# LPC865 register map
Vendor: nxp.com; File version: 1.0
CPU: CM0PLUS r0p0, little endian, no MPU, no FPU, VTOR, 2 interrupt priority bits
Registers are 32-bit, read-write, reset 0x0 unless marked. A register's access mark holds for its fields unless they carry their own. Offsets are from the block's base; [hi:lo] are bit positions; {n}, {i} and the like mark numbered series; 'fields as' and 'values as' point back to an identical list.

## ADC0 — LPC84x 12-bit ADC controller (ADC)
Base 0x4001C000
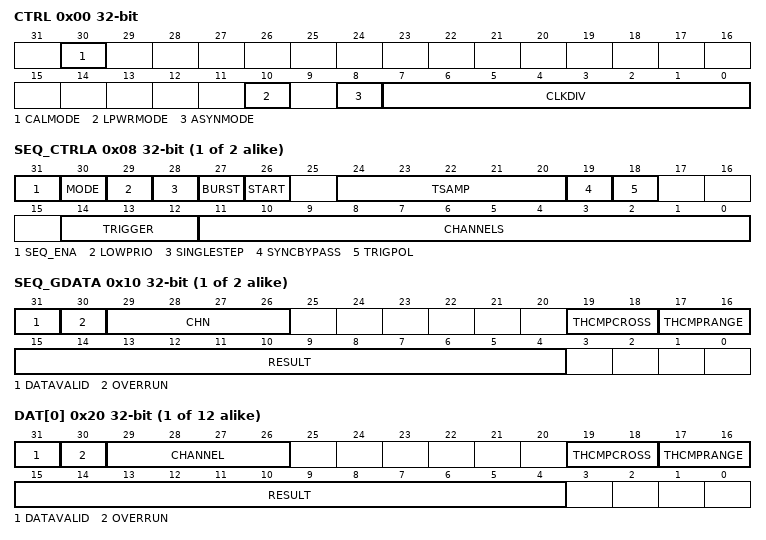
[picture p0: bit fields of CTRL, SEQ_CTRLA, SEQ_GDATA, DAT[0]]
0x00 CTRL — ADC Control register. Contains the clock divide value, resolution selection, sampling time selection, and mode controls.
  [30] CALMODE — Writing a '1' to this bit will initiate a sef-calibration cycle. This bit will be automatically cleared by hardware after the calibration cycle is complete. Note: Other bits of this register may be written to concurrently with setting this bit, however once this bit has been set no further writes to this register are permitted unitl the full calibration cycle has ended.
  [10] LPWRMODE — The low-power ADC mode
    0=The low-power ADC mode is disabled. The analog circuitry remains activated even when no conversions are requested.; 1=The low-power ADC mode is enabled. The analog circuitry is automatically powered-down when no conversions are taking place. When any (hardware or software) triggering event is detected, the analog circuitry is enabled. After the required start-up time, the requested conversion will be launched. Once the conversion completes, the analog-circuitry will again be powered-down provided no further conversions are pending. Using this mode can save an appreciable amount of current (approximately 2.5 mA) when conversions are required relatively infrequently. The penalty for using this mode is an approximately FIFTEEN ADC CLOCK delay (30 clocks in 10-bit mode), based on the frequency specified in the CLKDIV field, from the time the trigger event occurs until sampling of the A/D input commences. Note: This mode will NOT power-up the A/D if the ADC_ENA bit is low.
  [8] ASYNMODE — Select clock mode.
    0=SYNCHRONOUS_MODE (Synchronous mode. The ADC clock is derived from the system clock based on the divide value selected in the CLKDIV field. The ADC clock will be started in a controlled fashion in response to a trigger to eliminate any uncertainty in the launching of an ADC conversion in response to any synchronous (on-chip) trigger. In Synchronous mode with the SYNCBYPASS bit (in a sequence control register) set, sampling of the ADC input and start of conversion will initiate 2 system clocks after the leading edge of a (synchronous) trigger pulse.); 1=ASYNCHRONOUS_MODE (Asynchronous mode. The ADC clock is based on the output of the ADC clock divider ADCCLKSEL in the SYSCON block.)
  [7:0] CLKDIV — In synchronous mode only, the system clock is divided by this value plus one to produce the clock for the ADC converter, which should be less than or equal to 72 MHz. Typically, software should program the smallest value in this field that yields this maximum clock rate or slightly less, but in certain cases (such as a high-impedance analog source) a slower clock may be desirable. This field is ignored in the asynchronous operating mode.
0x08 SEQ_CTRL{x} (x=A,B; step 0x4) (reset mask 0xFC0FFFFF) — ADC Conversion Sequence-n control register: Controls triggering and channel selection for conversion sequence-n. Also specifies interrupt mode for sequence-n.
  [31] SEQ_ENA — Sequence Enable. In order to avoid spuriously triggering the sequence, care should be taken to only set the SEQn_ENA bit when the selected trigger input is in its INACTIVE state (as defined by the TRIGPOL bit). If this condition is not met, the sequence will be triggered immediately upon being enabled. In order to avoid spuriously triggering the sequence, care should be taken to only set the SEQn_ENA bit when the selected trigger input is in its INACTIVE state (as defined by the TRIGPOL bit). If this condition is not met, the sequence will be triggered immediately upon being enabled.
    0=DISABLED (Disabled. Sequence n is disabled. Sequence n triggers are ignored. If this bit is cleared while sequence n is in progress, the sequence will be halted at the end of the current conversion. After the sequence is re-enabled, a new trigger will be required to restart the sequence beginning with the next enabled channel.); 1=ENABLED (Enabled. Sequence n is enabled.)
  [30] MODE — Indicates whether the primary method for retrieving conversion results for this sequence will be accomplished via reading the global data register (SEQA_GDAT) at the end of each conversion, or the individual channel result registers at the end of the entire sequence. Impacts when conversion-complete interrupt/DMA trigger for sequence-A will be generated and which overrun conditions contribute to an overrun interrupt as described below.
    0=END_OF_CONVERSION (End of conversion. The sequence A interrupt/DMA trigger will be set at the end of each individual ADC conversion performed under sequence A. This flag will mirror the DATAVALID bit in the SEQA_GDAT register. The OVERRUN bit in the SEQA_GDAT register will contribute to generation of an overrun interrupt/DMA trigger if enabled.); 1=END_OF_SEQUENCE (End of sequence. The sequence A interrupt/DMA trigger will be set when the entire set of sequence-A conversions completes. This flag will need to be explicitly cleared by software or by the DMA-clear signal in this mode. The OVERRUN bit in the SEQA_GDAT register will NOT contribute to generation of an overrun interrupt/DMA trigger since it is assumed this register may not be utilized in this mode.)
  [29] LOWPRIO — Set priority for sequence A.
    0=LOW_PRIORITY (Low priority. Any B trigger which occurs while an A conversion sequence is active will be ignored and lost.); 1=HIGH_PRIORITY (High priority. Setting this bit to a 1 will permit any enabled B sequence trigger (including a B sequence software start) to immediately interrupt sequence A and launch a B sequence in it's place. The conversion currently in progress will be terminated. The A sequence that was interrupted will automatically resume after the B sequence completes. The channel whose conversion was terminated will be re-sampled and the conversion sequence will resume from that point.)
  [28] SINGLESTEP — When this bit is set, a hardware trigger or a write to the START bit will launch a single conversion on the next channel in the sequence instead of the default response of launching an entire sequence of conversions. Once all of the channels comprising a sequence have been converted, a subsequent trigger will repeat the sequence beginning with the first enabled channel. Interrupt generation will still occur either after each individual conversion or at the end of the entire sequence, depending on the state of the MODE bit.
  [27] BURST — Writing a 1 to this bit will cause this conversion sequence to be continuously cycled through. Other sequence A triggers will be ignored while this bit is set. Repeated conversions can be halted by clearing this bit. The sequence currently in progress will be completed before conversions are terminated. Note that a new sequence could begin just before BURST is cleared.
  [26] START — Writing a 1 to this field will launch one pass through this conversion sequence. The behavior will be identical to a sequence triggered by a hardware trigger. Do not write 1 to this bit if the BURST bit is set. This bit is only set to a 1 momentarily when written to launch a conversion sequence. It will consequently always read back as a zero.
  [24:20] TSAMP — The default sample period (TSAMP = "00000") at the beginning of each new conversion is 6.5 ADC clock periods. Depending on avariety of factors including ADC clock rate, output impedance of the analog source driver, ADC resolution, and the selection of channels, the sample time may need to be increased. The value programmed into the TSAMP fields dictates the number of additional ADC clock cycles (beyond 6.5) that the sample period will be extended by. Note: Any additional clocks of sample time inserted will add directly to the overall number of clocks required for a conversion, effectivelyreducing the overall conversion throughput rate.
  [19] SYNCBYPASS — Setting this bit allows the hardware trigger input to bypass synchronization flip-flop stages and therefore shorten the time between the trigger input signal and the start of a conversion. There are slightly different criteria for whether or not this bit can be set depending on the clock operating mode: Synchronous mode (the ASYNMODE in the CTRL register = 0): Synchronization may be bypassed (this bit may be set) if the selected trigger source is already synchronous with the main system clock (eg. coming from an on-chip, system-clock-based timer). Whether this bit is set or not, a trigger pulse must be maintained for at least one system clock period. Asynchronous mode (the ASYNMODE in the CTRL register = 1): Synchronization may be bypassed (this bit may be set) if it is certain that the duration of a trigger input pulse will be at least one cycle of the ADC clock (regardless of whether the trigger comes from and on-chip or off-chip source). If this bit is NOT set, the trigger pulse must at least be maintained for one system clock period.
    0=ENABLE_TRIGGER_SYNCH (Enable trigger synchronization. The hardware trigger bypass is not enabled.); 1=BYPASS_TRIGGER_SYNCH (Bypass trigger synchronization. The hardware trigger bypass is enabled.)
  [18] TRIGPOL — Select the polarity of the selected input trigger for this conversion sequence. In order to avoid generating a spurious trigger, it is recommended writing to this field only when SEQA_ENA (bit 31) is low. It is safe to change this field and set bit 31 in the same write.
    0=NEGATIVE_EDGE (Negative edge. A negative edge launches the conversion sequence on the selected trigger input.); 1=POSITIVE_EDGE (Positive edge. A positive edge launches the conversion sequence on the selected trigger input.)
  [14:12] TRIGGER — Selects which of the available hardware trigger sources will cause this conversion sequence to be initiated. Program the trigger input number in this field. See Table 476. In order to avoid generating a spurious trigger, it is recommended writing to this field only when SEQA_ENA (bit 31) is low. It is safe to change this field and set bit 31 in the same write.
  [11:0] CHANNELS — Selects which one or more of the ADC channels will be sampled and converted when this sequence is launched. A 1 in any bit of this field will cause the corresponding channel to be included in the conversion sequence, where bit 0 corresponds to channel 0, bit 1 to channel 1 and so forth. When this conversion sequence is triggered, either by a hardware trigger or via software command, ADC conversions will be performed on each enabled channel, in sequence, beginning with the lowest-ordered channel. This field can ONLY be changed while SEQA_ENA (bit 31) is LOW. It is allowed to change this field and set bit 31 in the same write.
0x10 SEQ_GDAT{x} (x=A,B; step 0x4) ro — ADC Sequence-n Global Data register. This register contains the result of the most recent ADC conversion performed under sequence-n.
  [31] DATAVALID — This bit is set to '1' at the end of each conversion when a new result is loaded into the RESULT field. It is cleared whenever this register is read. This bit will cause a conversion-complete interrupt for the corresponding sequence if the MODE bit (in SEQA_CTRL) for that sequence is set to 0 (and if the interrupt is enabled).
  [30] OVERRUN — This bit is set if a new conversion result is loaded into the RESULT field before a previous result has been read - i.e. while the DATAVALID bit is set. This bit is cleared, along with the DATAVALID bit, whenever this register is read. This bit will contribute to an overrun interrupt/DMA trigger if the MODE bit (in SEQAA_CTRL) for the corresponding sequence is set to '0' (and if the overrun interrupt is enabled).
  [29:26] CHN — These bits contain the channel from which the RESULT bits were converted (e.g. 0000 identifies channel 0, 0001 channel 1, etc.).
  [19:18] THCMPCROSS — Indicates whether the result of the last conversion performed represented a crossing of the threshold level established by the designated LOW threshold comparison register (THRn_LOW) and, if so, in what direction the crossing occurred.
  [17:16] THCMPRANGE — Indicates whether the result of the last conversion performed was above, below or within the range established by the designated threshold comparison registers (THRn_LOW and THRn_HIGH).
  [15:4] RESULT — This field contains the 12-bit ADC conversion result from the most recent conversion performed under conversion sequence associated with this register. The result is a binary fraction representing the voltage on the currently-selected input channel as it falls within the range of VREFP to VREFN. Zero in the field indicates that the voltage on the input pin was less than, equal to, or close to that on VREFN, while 0xFFF indicates that the voltage on the input was close to, equal to, or greater than that on VREFP. DATAVALID = 1 indicates that this result has not yet been read.
{0x20+4i} DAT[{i}] (i=0..11) ro — ADC Channel N Data register. This register contains the result of the most recent conversion completed on channel N.
  [31] DATAVALID — This bit is set to 1 when an ADC conversion on this channel completes. This bit is cleared whenever this register is read or when the data related to this channel is read from either of the global SEQn_GDAT registers. While it is allowed to include the same channels in both conversion sequences, doing so may cause erratic behavior of the DONE and OVERRUN bits in the data registers associated with any of the channels that are shared between the two sequences. Any erratic OVERRUN behavior will also affect overrun interrupt generation, if enabled.
  [30] OVERRUN — This bit will be set to a 1 if a new conversion on this channel completes and overwrites the previous contents of the RESULT field before it has been read - i.e. while the DONE bit is set. This bit is cleared, along with the DONE bit, whenever this register is read or when the data related to this channel is read from either of the global SEQn_GDAT registers. This bit (in any of the 12 registers) will cause an overrun interrupt/DMA trigger to be asserted if the overrun interrupt is enabled. While it is allowed to include the same channels in both conversion sequences, doing so may cause erratic behavior of the DONE and OVERRUN bits in the data registers associated with any of the channels that are shared between the two sequences. Any erratic OVERRUN behavior will also affect overrun interrupt generation, if enabled.
  [29:26] CHANNEL — This field is hard-coded to contain the channel number that this particular register relates to (i.e. this field will contain 0b0000 for the DAT0 register, 0b0001 for the DAT1 register, etc)
  [19:18] THCMPCROSS — Threshold Crossing Comparison result. 0x0 = No threshold Crossing detected: The most recent completed conversion on this channel had the same relationship (above or below) to the threshold value established by the designated LOW threshold register (THRn_LOW) as did the previous conversion on this channel. 0x1 = Reserved. 0x2 = Downward Threshold Crossing Detected. Indicates that a threshold crossing in the downward direction has occurred - i.e. the previous sample on this channel was above the threshold value established by the designated LOW threshold register (THRn_LOW) and the current sample is below that threshold. 0x3 = Upward Threshold Crossing Detected. Indicates that a threshold crossing in the upward direction has occurred - i.e. the previous sample on this channel was below the threshold value established by the designated LOW threshold register (THRn_LOW) and the current sample is above that threshold.
  [17:16] THCMPRANGE — Threshold Range Comparison result. 0x0 = In Range: The last completed conversion was greater than or equal to the value programmed into the designated LOW threshold register (THRn_LOW) but less than or equal to the value programmed into the designated HIGH threshold register (THRn_HIGH). 0x1 = Below Range: The last completed conversion on was less than the value programmed into the designated LOW threshold register (THRn_LOW). 0x2 = Above Range: The last completed conversion was greater than the value programmed into the designated HIGH threshold register (THRn_HIGH). 0x3 = Reserved.
  [15:4] RESULT — This field contains the 12-bit ADC conversion result from the last conversion performed on this channel. This will be a binary fraction representing the voltage on the AD0[n] pin, as it falls within the range of VREFP to VREFN. Zero in the field indicates that the voltage on the input pin was less than, equal to, or close to that on VREFN, while 0xFFF indicates that the voltage on the input was close to, equal to, or greater than that on VREFP.
0x50 THR0_LOW — ADC Low Compare Threshold register 0: Contains the lower threshold level for automatic threshold comparison for any channels linked to threshold pair 0.
  [15:4] THRLOW — Low threshold value against which ADC results will be compared
0x54 THR1_LOW — ADC Low Compare Threshold register 1: Contains the lower threshold level for automatic threshold comparison for any channels linked to threshold pair 1.
  fields as THR0_LOW
0x58 THR0_HIGH — ADC High Compare Threshold register 0: Contains the upper threshold level for automatic threshold comparison for any channels linked to threshold pair 0.
  [15:4] THRHIGH — High threshold value against which ADC results will be compared
0x5C THR1_HIGH — ADC High Compare Threshold register 1: Contains the upper threshold level for automatic threshold comparison for any channels linked to threshold pair 1.
  fields as THR0_HIGH
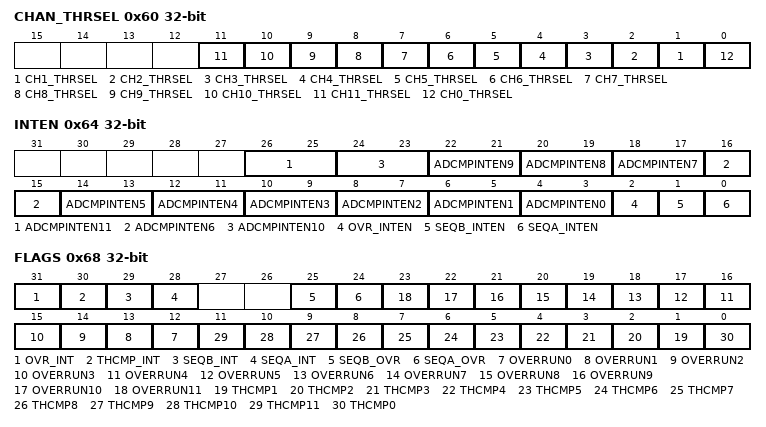
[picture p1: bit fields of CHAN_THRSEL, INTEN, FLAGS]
0x60 CHAN_THRSEL — ADC Channel-Threshold Select register. Specifies which set of threshold compare registers are to be used for each channel
  [n] CH{n}_THRSEL (n=1..11) — Threshold select for channel {n}. See description for channel 0.
  [0] CH0_THRSEL — Threshold select for channel 0.
    0=THRESHOLD0 (Threshold 0. Results for this channel will be compared against the threshold levels indicated in the THR0_LOW and THR0_HIGH registers.); 1=THRESHOLD1 (Threshold 1. Results for this channel will be compared against the threshold levels indicated in the THR1_LOW and THR1_HIGH registers.)
0x64 INTEN — ADC Interrupt Enable register. This register contains enable bits that enable the sequence-A, sequence-B, threshold compare and data overrun interrupts to be generated.
  [26:25] ADCMPINTEN11 — Channel 21 threshold comparison interrupt enable. See description for channel 0.
  [2n+4:2n+3] ADCMPINTEN{n} (n=1..10) — Channel {n} threshold comparison interrupt enable. See description for channel 0.
  [4:3] ADCMPINTEN0 — Threshold comparison interrupt enable for channel 0.
    0=DISABLED; 1=OUTSIDE_THRESHOLD; 2=CROSSING_THRESHOLD
  [2] OVR_INTEN — Overrun interrupt enable.
    0=DISABLED (Disabled. The overrun interrupt is disabled.); 1=ENABLED (Enabled. The overrun interrupt is enabled. Detection of an overrun condition on any of the 12 channel data registers will cause an overrun interrupt/DMA trigger. In addition, if the MODE bit for a particular sequence is 0, then an overrun in the global data register for that sequence will also cause this interrupt/DMA trigger to be asserted.)
  [1] SEQB_INTEN — Sequence B interrupt enable.
    0=DISABLED (Disabled. The sequence B interrupt/DMA trigger is disabled.); 1=ENABLED (Enabled. The sequence B interrupt/DMA trigger is enabled and will be asserted either upon completion of each individual conversion performed as part of sequence B, or upon completion of the entire B sequence of conversions, depending on the MODE bit in the SEQB_CTRL register.)
  [0] SEQA_INTEN — Sequence A interrupt enable.
    0=DISABLED (Disabled. The sequence A interrupt/DMA trigger is disabled.); 1=ENABLED (Enabled. The sequence A interrupt/DMA trigger is enabled and will be asserted either upon completion of each individual conversion performed as part of sequence A, or upon completion of the entire A sequence of conversions, depending on the MODE bit in the SEQA_CTRL register.)
0x68 FLAGS — ADC Flags register. Contains the four interrupt/DMA trigger flags and the individual component overrun and threshold-compare flags. (The overrun bits replicate information stored in the result registers).
  [31] OVR_INT ro — Overrun Interrupt flag. Any overrun bit in any of the individual channel data registers will cause this interrupt. In addition, if the MODE bit in either of the SEQn_CTRL registers is 0 then the OVERRUN bit in the corresponding SEQn_GDAT register will also cause this interrupt. This interrupt must be enabled in the INTEN register. This bit will be cleared when all of the individual overrun bits have been cleared via reading the corresponding data registers.
  [30] THCMP_INT ro — Threshold Comparison Interrupt. This bit will be set if any of the THCMP flags in the lower bits of this register are set to 1 (due to an enabled out-of-range or threshold-crossing event on any channel). Each type of threshold comparison interrupt on each channel must be individually enabled in the INTEN register to cause this interrupt. This bit will be cleared when all of the individual threshold flags are cleared via writing 1s to those bits.
  [29] SEQB_INT ro — Sequence A interrupt/DMA trigger. If the MODE bit in the SEQB_CTRL register is 0, this flag will mirror the DATAVALID bit in the sequence A global data register (SEQB_GDAT), which is set at the end of every ADC conversion performed as part of sequence B. It will be cleared automatically when the SEQB_GDAT register is read. If the MODE bit in the SEQB_CTRL register is 1, this flag will be set upon completion of an entire B sequence. In this case it must be cleared by writing a 1 to this SEQB_INT bit. This interrupt must be enabled in the INTEN register.
  [28] SEQA_INT ro — Sequence A interrupt/DMA trigger. If the MODE bit in the SEQA_CTRL register is 0, this flag will mirror the DATAVALID bit in the sequence A global data register (SEQA_GDAT), which is set at the end of every ADC conversion performed as part of sequence A. It will be cleared automatically when the SEQA_GDAT register is read. If the MODE bit in the SEQA_CTRL register is 1, this flag will be set upon completion of an entire A sequence. In this case it must be cleared by writing a 1 to this SEQA_INT bit. This interrupt must be enabled in the INTEN register.
  [25] SEQB_OVR ro — Mirrors the global OVERRUN status flag in the SEQB_GDAT register
  [24] SEQA_OVR ro — Mirrors the global OVERRUN status flag in the SEQA_GDAT register
  [n+12] OVERRUN{n} ro (n=0..11) — Mirrors the OVERRRUN status flag from the result register for ADC channel {n}
  [n] THCMP{n} (n=1..11) — Threshold comparison event on Channel {n}. See description for channel 0.
  [0] THCMP0 — Threshold comparison event on Channel 0. Set to 1 upon either an out-of-range result or a threshold-crossing result if enabled to do so in the INTEN register. This bit is cleared by writing a 1.
0x6C TRM — ADC Startup register.
  [5] VRANGE — 1.8V to 3.6V Vdd range: This bit MUST be set to '1' if operation below 2.7V is to be used. Failure to set this bit will result in invalid ADC results. Note: This bit will not be spec'd on parts that do not support operation below 2.7V
